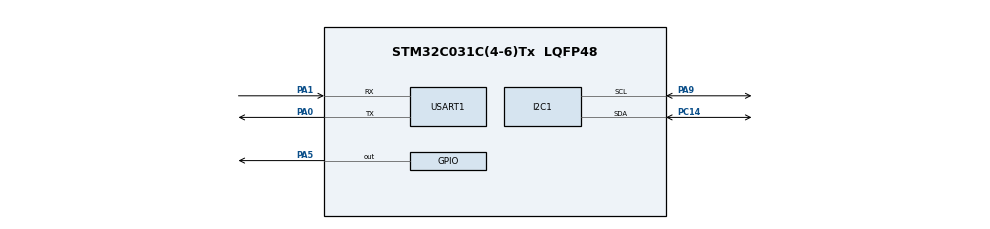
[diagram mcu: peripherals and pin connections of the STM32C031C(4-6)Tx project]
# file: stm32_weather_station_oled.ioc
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I2C1.Timing=0x00402D41
Mcu.Family=STM32C0
Mcu.Name=STM32C031C(4-6)Tx
Mcu.Package=LQFP48
NVIC.I2C1_IRQn=true\:0\:0\:false\:false\:true\:true\:true\:true
NVIC.USART1_IRQn=true\:0\:0\:false\:false\:true\:true\:true\:true
PA0.Mode=Asynchronous
PA0.Signal=USART1_TX
PA1.Mode=Asynchronous
PA1.Signal=USART1_RX
PA5.Signal=GPIO_Output
PA9.Mode=I2C
PA9.Signal=I2C1_SCL
PC14-OSCX_IN\ (PC14).Mode=I2C
PC14-OSCX_IN\ (PC14).Signal=I2C1_SDA
ProjectManager.HeapSize=0x200
ProjectManager.StackSize=0x400
ProjectManager.TargetToolchain=STM32CubeIDE
RCC.ADCFreq_Value=12000000
RCC.AHBFreq_Value=12000000
RCC.CortexFreq_Value=12000000
RCC.EXTERNAL_CLOCK_VALUE=12288000
RCC.HCLKFreq_Value=12000000
RCC.HSE_VALUE=8000000
RCC.HSI_VALUE=48000000
RCC.LSE_VALUE=32768
RCC.SYSCLKFreq_VALUE=12000000
USART1.VirtualMode-Asynchronous=VM_ASYNC
board=custom

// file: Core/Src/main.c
/* USER CODE BEGIN Header */
/**
  ******************************************************************************
  * @file           : main.c
  * @brief          : Main program body
  ******************************************************************************
  * @attention
  *
  * Copyright (c) 2026 STMicroelectronics.
  * All rights reserved.
  *
  * This software is licensed under terms that can be found in the LICENSE file
  * in the root directory of this software component.
  * If no LICENSE file comes with this software, it is provided AS-IS.
  *
  ******************************************************************************
  */
/* USER CODE END Header */
#include "main.h"

I2C_HandleTypeDef hi2c1;

UART_HandleTypeDef huart1;

/* USER CODE BEGIN PV */
#define UART_BUF_LENGTH 100
uint8_t TxBuf[UART_BUF_LENGTH] = "AT+GMR\r\n";
uint8_t RxBuf[UART_BUF_LENGTH];
uint8_t TxReady = 1;
/* USER CODE END PV */

void SystemClock_Config(void);
static void MX_GPIO_Init(void);
static void MX_I2C1_Init(void);
static void MX_USART1_UART_Init(void);

int main(void)
{

  /* MCU Configuration--------------------------------------------------------*/

  /* Reset of all peripherals, Initializes the Flash interface and the Systick. */
  HAL_Init();

  /* Configure the system clock */
  SystemClock_Config();

  /* Initialize all configured peripherals */
  MX_GPIO_Init();
  MX_I2C1_Init();
  MX_USART1_UART_Init();
  /* USER CODE BEGIN 2 */
  HAL_UART_Transmit(&huart1, TxBuf,strlen((char*)TxBuf), HAL_MAX_DELAY);
  HAL_UART_Receive_IT(&huart1, RxBuf, UART_BUF_LENGTH);

  /* USER CODE END 2 */

  /* Infinite loop */
  while (1)
  {

  }
}

void SystemClock_Config(void)
{
  RCC_OscInitTypeDef RCC_OscInitStruct = {0};
  RCC_ClkInitTypeDef RCC_ClkInitStruct = {0};

  __HAL_FLASH_SET_LATENCY(FLASH_LATENCY_0);

  /** Initializes the RCC Oscillators according to the specified parameters
  * in the RCC_OscInitTypeDef structure.
  */
  RCC_OscInitStruct.OscillatorType = RCC_OSCILLATORTYPE_HSI;
  RCC_OscInitStruct.HSIState = RCC_HSI_ON;
  RCC_OscInitStruct.HSIDiv = RCC_HSI_DIV4;
  RCC_OscInitStruct.HSICalibrationValue = RCC_HSICALIBRATION_DEFAULT;
  if (HAL_RCC_OscConfig(&RCC_OscInitStruct) != HAL_OK)
  {
    Error_Handler();
  }

  /** Initializes the CPU, AHB and APB buses clocks
  */
  RCC_ClkInitStruct.ClockType = RCC_CLOCKTYPE_HCLK|RCC_CLOCKTYPE_SYSCLK
                              |RCC_CLOCKTYPE_PCLK1;
  RCC_ClkInitStruct.SYSCLKSource = RCC_SYSCLKSOURCE_HSI;
  RCC_ClkInitStruct.SYSCLKDivider = RCC_SYSCLK_DIV1;
  RCC_ClkInitStruct.AHBCLKDivider = RCC_HCLK_DIV1;
  RCC_ClkInitStruct.APB1CLKDivider = RCC_APB1_DIV1;

  if (HAL_RCC_ClockConfig(&RCC_ClkInitStruct, FLASH_LATENCY_0) != HAL_OK)
  {
    Error_Handler();
  }
}

static void MX_I2C1_Init(void)
{

  hi2c1.Instance = I2C1;
  hi2c1.Init.Timing = 0x00402D41;
  hi2c1.Init.OwnAddress1 = 0;
  hi2c1.Init.AddressingMode = I2C_ADDRESSINGMODE_7BIT;
  hi2c1.Init.DualAddressMode = I2C_DUALADDRESS_DISABLE;
  hi2c1.Init.OwnAddress2 = 0;
  hi2c1.Init.OwnAddress2Masks = I2C_OA2_NOMASK;
  hi2c1.Init.GeneralCallMode = I2C_GENERALCALL_DISABLE;
  hi2c1.Init.NoStretchMode = I2C_NOSTRETCH_DISABLE;
  if (HAL_I2C_Init(&hi2c1) != HAL_OK)
  {
    Error_Handler();
  }

  /** Configure Analogue filter
  */
  if (HAL_I2CEx_ConfigAnalogFilter(&hi2c1, I2C_ANALOGFILTER_ENABLE) != HAL_OK)
  {
    Error_Handler();
  }

  /** Configure Digital filter
  */
  if (HAL_I2CEx_ConfigDigitalFilter(&hi2c1, 0) != HAL_OK)
  {
    Error_Handler();
  }

}

static void MX_USART1_UART_Init(void)
{

  huart1.Instance = USART1;
  huart1.Init.BaudRate = 115200;
  huart1.Init.WordLength = UART_WORDLENGTH_8B;
  huart1.Init.StopBits = UART_STOPBITS_1;
  huart1.Init.Parity = UART_PARITY_NONE;
  huart1.Init.Mode = UART_MODE_TX_RX;
  huart1.Init.HwFlowCtl = UART_HWCONTROL_NONE;
  huart1.Init.OverSampling = UART_OVERSAMPLING_16;
  huart1.Init.OneBitSampling = UART_ONE_BIT_SAMPLE_DISABLE;
  huart1.Init.ClockPrescaler = UART_PRESCALER_DIV1;
  huart1.AdvancedInit.AdvFeatureInit = UART_ADVFEATURE_NO_INIT;
  if (HAL_UART_Init(&huart1) != HAL_OK)
  {
    Error_Handler();
  }
  if (HAL_UARTEx_SetTxFifoThreshold(&huart1, UART_TXFIFO_THRESHOLD_1_8) != HAL_OK)
  {
    Error_Handler();
  }
  if (HAL_UARTEx_SetRxFifoThreshold(&huart1, UART_RXFIFO_THRESHOLD_1_8) != HAL_OK)
  {
    Error_Handler();
  }
  if (HAL_UARTEx_DisableFifoMode(&huart1) != HAL_OK)
  {
    Error_Handler();
  }

}

static void MX_GPIO_Init(void)
{
  GPIO_InitTypeDef GPIO_InitStruct = {0};

  /* GPIO Ports Clock Enable */
  __HAL_RCC_GPIOC_CLK_ENABLE();
  __HAL_RCC_GPIOA_CLK_ENABLE();

  /*Configure GPIO pin Output Level */
  HAL_GPIO_WritePin(GPIOA, GPIO_PIN_5, GPIO_PIN_SET);

  /*Configure GPIO pin : PA5 */
  GPIO_InitStruct.Pin = GPIO_PIN_5;
  GPIO_InitStruct.Mode = GPIO_MODE_OUTPUT_PP;
  GPIO_InitStruct.Pull = GPIO_NOPULL;
  GPIO_InitStruct.Speed = GPIO_SPEED_FREQ_LOW;
  HAL_GPIO_Init(GPIOA, &GPIO_InitStruct);

}

/* USER CODE BEGIN 4 */
void HAL_UART_RxCpltCallback(UART_HandleTypeDef *huart)
{
    if(huart->Instance == USART1)
    {
        if(strstr((char*)RxBuf, "OK") != NULL)
        {
            HAL_GPIO_TogglePin(GPIOA, GPIO_PIN_5);
        }
        memset(RxBuf, 0, UART_BUF_LENGTH);
        HAL_UART_Receive_IT(&huart1, RxBuf, UART_BUF_LENGTH);
    }
}

/* USER CODE END 4 */

void Error_Handler(void)
{
  __disable_irq();
  while (1)
  {
  }
}
